# nRF7140_graphics register map
Vendor: Nordic Semiconductor; Series: nRF71; File version: 1
CPU: CM33 r0p4, little endian, MPU, FPU, 3 interrupt priority bits, 480 interrupts
Registers are 32-bit, read-write, reset 0x0 unless marked. A register's access mark holds for its fields unless they carry their own. Offsets are from the block's base; [hi:lo] are bit positions; lines under a group give offsets from that group; {n}, {i} and the like mark numbered series; 'fields as' and 'values as' point back to an identical list.

## GLOBAL_FICR_NS — Factory Information Configuration Registers
Base 0x0FFFE000
0x00 SOCINFO group — Unspecified
  0x00 PARTNO ro reset 0xFFFFFFFF — Part number.
    [31:0] PART
  0x04 HWREVISION ro reset 0xFFFFFFFF — Hardware revision.
    [31:0] HWREVISION — Hardvare revision.
  0x08 PRODUCTIONREVISION ro reset 0xFFFFFFFF — Production reversion.
0x0C BLE group — Unspecified
  0x00 ADDRTYPE ro reset 0xFFFFFFFF — Device address type.
    [0] TYPE
      0=Public address; 1=Random address
  {0x4+4j} ADDR[{j}] (j=0..1) ro reset 0xFFFFFFFF — Description collection: 48 bit device address.
    [31:0] ADDR — Device address [n].
  {0xC+4j} ER[{j}] (j=0..3) ro reset 0xFFFFFFFF — Description collection: Encryption Root.
    [31:0] ER — Encryption root word [n].
  {0x1C+4j} IR[{j}] (j=0..3) ro reset 0xFFFFFFFF — Description collection: Identity Root.
    [31:0] IR — Identity root word [n].
0x40 NFC group — Unspecified
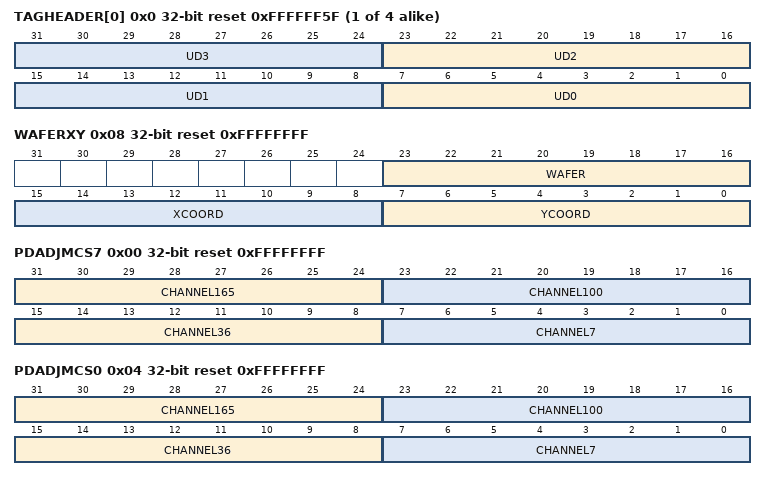
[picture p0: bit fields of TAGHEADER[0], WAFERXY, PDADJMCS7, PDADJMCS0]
  {0x0+4j} TAGHEADER[{j}] (j=0..3) ro reset 0xFFFFFF5F — Description collection: Default header for NFC Tag.
    [8n+7:8n] UD{n} (n=0..3) — Unique identifier byte {n}
0x50 INFO group — Device info
  0x00 CONFIGID ro reset 0xFFFFFFFF — Configuration identifier
    [15:0] HWID — Identification number for the HW
  0x04 PART ro reset 0xFFFFFFFF — Part code
    [31:0] PART
      0xFFFFFFFF=Unspecified
  0x08 VARIANT ro reset 0xFFFFFFFF — Part Variant, Hardware version and Production configuration
    [31:0] VARIANT — Part Variant, Hardware version and Production configuration, encoded as ASCII
      0xFFFFFFFF=Unspecified
  0x0C PACKAGE ro reset 0xFFFFFFFF — Package option
    [31:0] PACKAGE
      0xFFFFFFFF=Unspecified
  0x10 RAM ro reset 0xFFFFFFFF — RAM variant
    [31:0] RAM
      0xFFFFFFFF=Unspecified
  0x14 MRAM ro reset 0xFFFFFFFF — MRAM variant
    [31:0] MRAM
      0xFFFFFFFF=Unspecified
  0x18 CODEPAGESIZE ro reset 0x1000 — Code memory page size in bytes
    [31:0] CODEPAGESIZE
      0xFFFFFFFF=Unspecified
  0x1C CODESIZE ro reset 0x100 — Code memory size
    [31:0] CODESIZE — Code memory size in number of pages
      0xFFFFFFFF=Unspecified
  0x20 DEVICETYPE ro
    [31:0] DEVICETYPE
      0=Die (Device is an physical DIE); 0xFFFFFFFF=FPGA (Device is an FPGA)
0x80 WIFI group — Unspecified
  0x00 DISABLE5GHZ ro reset 0xFFFFFFFF
    [31:0] VALUE — Disable 5GHz support. Firmware reads at start of day. Set to 0x50FA50FA to disable 5GHz operation.
  {0x4+4j} MACADDR0[{j}] (j=0..2) ro reset 0xFFFFFFFF — Description collection: Least significant 4 bytes of default MAC address for VIF[n].
    [31:0] MACADDRLO — MAC address for VIF[n] bytes 3:0.
  {0x10+4j} MACADDR1[{j}] (j=0..2) ro reset 0xFFFFFFFF — Description collection: Most significant 2 bytes of default MAC address for VIF[n].
    [15:0] MACADDRHI — MAC address for VIF[n] bytes 5:4.
0xC0 PRODTEST group — Unspecified
  0x00 CP group — Unspecified
    {0x0+4k} LOTNR[{k}] (k=0..1) ro reset 0xFFFFFFFF — Description collection: Lot number.
      [31:0] LOTNR — Lot number
    0x08 WAFERXY ro reset 0xFFFFFFFF — Wafer number and die X,Y coordinate.
      [23:16] WAFER — Wafer number
      [15:8] XCOORD — Die x coordinate
      [7:0] YCOORD — Die y coordinate
    0x0C PROGVERSION1 ro reset 0xFFFFFFFF — CP1 test program version.
      [31:0] PROGVERSION1 — CP1 test program version
    0x10 PROGVERSION2 ro reset 0xFFFFFFFF — CP2 test program version.
      [31:0] PROGVERSION2 — CP2 test program version
  0x14 FT group — Unspecified
    0x00 PROGVERSION1 ro reset 0xFFFFFFFF — FT1 test program version.
      [31:0] PROGVERSION1 — FT1 test program version
    0x04 PROGVERSION2 ro reset 0xFFFFFFFF — FT2 test program version.
      [31:0] PROGVERSION2 — FT2 test program version
0x100 TRIM group — Unspecified
  0x00 SYSCTRL group — Unspecified
    0x00 FLL16M group — Unspecified
      0x00 TRIM group — Unspecified
        0x00 RCOARSE ro reset 0xFFFFFFFF — Trim value for SYSCTRL.FLL16M.RCOARSE
          [31:0] VALUE — Trim value
        0x04 RFINE ro reset 0xFFFFFFFF — Trim value for SYSCTRL.FLL16M.RFINE
          [31:0] VALUE — Trim value
        0x08 TCOEF ro reset 0xFFFFFFFF — Trim value for SYSCTRL.FLL16M.TCOEF
          [31:0] VALUE — Trim value
        0x0C VSUP ro reset 0xFFFFFFFF — Trim value for SYSCTRL.FLL16M.VSUP
          [31:0] VALUE — Trim value
        0x10 CKSW16MTRIM ro reset 0xFFFFFFFF — Trim value for SYSCTRL.FLL16M.CKSW16MTRIM
          [31:0] VALUE — Trim value
    0x14 LFRC group — Unspecified
      0x00 CAL group — Unspecified
        0x00 LFRCOSCTRIM ro reset 0xFFFFFFFF — Trim value for SYSCTRL.LFRC.LFRCOSCTRIM
          [31:0] VALUE — Trim value
    0x18 LFXO group — Unspecified
      0x00 TRIM group — Unspecified
        0x00 PDLOWERTHR ro reset 0xFFFFFFFF — Trim value for SYSCTRL.LFXO.PDLOWERTHR
          [31:0] VALUE — Trim value
        0x04 PDUPPERTHR ro reset 0xFFFFFFFF — Trim value for SYSCTRL.LFXO.PDUPPERTHR
          [31:0] VALUE — Trim value
        0x08 BIAS ro reset 0xFFFFFFFF — Trim value for SYSCTRL.LFXO.BIAS
          [31:0] VALUE — Trim value
        0x0C PIXO ro reset 0xFFFFFFFF — Trim value for SYSCTRL.LFXO.PIXO
          [31:0] VALUE — Trim value
        0x10 TRIMBUS ro reset 0xFFFFFFFF — Trim value for SYSCTRL.LFXO.TRIMBUS
          [31:0] VALUE — Trim value
    0x2C HFXO64M group — Unspecified
      0x00 TRIM group — Unspecified
        0x00 DOUBLERCOMP ro reset 0xFFFFFFFF — Trim value for SYSCTRL.HFXO64M.TRIM.DOUBLERCOMP
          [31:0] VALUE — Trim value
        0x04 CHIRPTUNE ro reset 0xFFFFFFFF — Trim value for SYSCTRL.HFXO64M.TRIM.CHIRPTUNE
          [31:0] VALUE — Trim value
        0x08 RTUNE ro reset 0xFFFFFFFF — Trim value for SYSCTRL.HFXO64M.TRIM.RTUNE
          [31:0] VALUE — Trim value
    0x38 LFLPRC group — Unspecified
      0x00 VSUP ro reset 0xFFFFFFFF — Trim value for SYSCTRL.LFLPRC.VSUP
        [31:0] VALUE — Trim value
      0x04 RCOARSE ro reset 0xFFFFFFFF — Trim value for SYSCTRL.LFLPRC.RCOARSE
        [31:0] VALUE — Trim value
      0x08 RFINE ro reset 0xFFFFFFFF — Trim value for SYSCTRL.LFLPRC.RFINE
        [31:0] VALUE — Trim value
      0x0C PWMFINE ro reset 0xFFFFFFFF — Trim value for SYSCTRL.LFLPRC.PWMFINE
        [31:0] VALUE — Trim value
    0x48 VDETPOF5V0 group (alternate view of LFLPRC) — Unspecified
      0x00 TRIM group — Unspecified
        0x00 PWRGOOD ro reset 0xFFFFFFFF — Trim value for SYSCTRL.VDETPOF5V0.PWRGOOD
          [31:0] VALUE — Trim value
    0x4C VDETPOFVBAT group (alternate view of LFLPRC) — Unspecified
      0x00 TRIM group — Unspecified
        0x00 POFWARN ro reset 0xFFFFFFFF — Trim value for SYSCTRL.VDETPOFVBAT.POFWARN
          [31:0] VALUE — Trim value
    0x54 AUDIOPLL group — Unspecified
      0x00 TRIM group — Unspecified
        0x00 CTUNE ro reset 0xFFFFFFFF — Trim value for SYSCTRL.AUDIOPLL.CTUNE
          [31:0] VALUE — Trim value
    0x58 USBHSPLL group — Unspecified
      0x00 TRIM group — Unspecified
        0x00 CTUNE ro reset 0xFFFFFFFF — Trim value for SYSCTRL.USBHSPLL.CTUNE
          [31:0] VALUE — Trim value
    0x5C MBIAS group — Unspecified
      0x00 CONFIG group — Unspecified
        0x00 CFG ro reset 0xFFFFFFFF — Trim value for SYSCTRL.MBIAS.CFG
          [31:0] VALUE — Trim value
      0x04 TRIM group — Unspecified
        0x00 MBIASIBPP ro reset 0xFFFFFFFF — Trim value for SYSCTRL.MBIAS.MBIASIBPP
          [31:0] VALUE — Trim value
        0x04 MBIASIBPSR ro reset 0xFFFFFFFF — Trim value for SYSCTRL.MBIAS.MBIASIBPSR
          [31:0] VALUE — Trim value
    0x68 OSCRFR group — Unspecified
      0x00 TRIM group — Unspecified
        0x00 OSC ro reset 0xFFFFFFFF — Trim value for SYSCTRL.OSCRFR.OSC
          [31:0] VALUE — Trim value
        0x04 IBPSR ro reset 0xFFFFFFFF — Trim value for SYSCTRL.OSCRFR.IBPSR
          [31:0] VALUE — Trim value
    0x70 VREG1V0 group — Unspecified
      0x00 TRIM group — Unspecified
        0x00 IREF ro reset 0xFFFFFFFF — Trim value for SYSCTRL.VREG1V0.IREF
          [31:0] VALUE — Trim value
        0x04 HIGHPOWER ro reset 0xFFFFFFFF — Trim value for SYSCTRL.VREG1V0.HIGHPOWER
          [31:0] VALUE — Trim value
        0x08 LOWPOWER ro reset 0xFFFFFFFF — Trim value for SYSCTRL.VREG1V0.LOWPOWER
          [31:0] VALUE — Trim value
        0x0C ULPR ro reset 0xFFFFFFFF — Trim value for SYSCTRL.VREG1V0.ULPR
          [31:0] VALUE — Trim value
      0x10 VOUTHPNOMINAL ro reset 0xFFFFFFFF — Config value for SYSCTRL.VREG1V0.VOUTHPNOMINAL
        [31:0] VALUE — Trim value
    0x84 VREGAO0V8 group — Unspecified
      0x00 TRIM group — Unspecified
        0x00 IREF ro reset 0xFFFFFFFF — Trim value for SYSCTRL.VREGAO0V8.IREF
          [31:0] VALUE — Trim value
        0x04 HIGHPOWER ro reset 0xFFFFFFFF — Trim value for SYSCTRL.VREGAO0V8.HIGHPOWER
          [31:0] VALUE — Trim value
        0x08 LOWPOWER ro reset 0xFFFFFFFF — Trim value for SYSCTRL.VREGAO0V8.LOWPOWER
          [31:0] VALUE — Trim value
        0x0C ULTRALOWPOWER ro reset 0xFFFFFFFF — Trim value for SYSCTRL.VREGAO0V8.ULTRALOWPOWER
          [31:0] VALUE — Trim value
        0x10 BPDET ro reset 0xFFFFFFFF — Trim value for SYSCTRL.VREGAO0V8.BPDET
          [31:0] VALUE — Trim value
    0x98 VREGAO1V8 group — Unspecified
      0x00 TRIM group — Unspecified
        0x00 IREF ro reset 0xFFFFFFFF — Trim value for SYSCTRL.VREGAO1V8.IREF
          [31:0] VALUE — Trim value
        0x04 VREF ro reset 0xFFFFFFFF — Trim value for SYSCTRL.VREGAO1V8.VREF
          [31:0] VALUE — Trim value
        0x08 LOWPOWER ro reset 0xFFFFFFFF — Trim value for SYSCTRL.VREGAO1V8.LOWPOWER
          [31:0] VALUE — Trim value
        0x0C LOWPOWERDIFF ro reset 0xFFFFFFFF — Trim value for SYSCTRL.VREGAO1V8.LOWPOWERDIFF
          [31:0] VALUE — Trim value
    0xA8 VREGMAIN group — Unspecified
      0x00 TRIM group — Unspecified
        0x00 BIASIBPP ro reset 0xFFFFFFFF — Trim value for SYSCTRL.VREGMAIN.BIASIBPP
          [31:0] VALUE — Trim value
        0x04 BIASIBPSR ro reset 0xFFFFFFFF — Trim value for SYSCTRL.VREGMAIN.BIASIBPSR
          [31:0] VALUE — Trim value
        0x08 VDDAO1V8HYSTOUTPUT ro reset 0xFFFFFFFF — Trim value for SYSCTRL.VREGMAIN.VDDAO1V8HYSTOUTPUT
          [31:0] VALUE — Trim value
        0x0C VDDAO1V8PWMOUTPUT ro reset 0xFFFFFFFF — Trim value for SYSCTRL.VREGMAIN.VDDAO1V8PWMOUTPUT
          [31:0] VALUE — Trim value
        0x10 VDD1V0HYSTOUTPUT ro reset 0xFFFFFFFF — Trim value for SYSCTRL.VREGMAIN.VDD1V0HYSTOUTPUT
          [31:0] VALUE — Trim value
        0x14 VDDVS0V8HYSTOUTPUT ro reset 0xFFFFFFFF — Trim value for SYSCTRL.VREGMAIN.VDDVS0V8HYSTOUTPUT
          [31:0] VALUE — Trim value
        0x18 VDDVS0V8PWMOUTPUT ro reset 0xFFFFFFFF — Trim value for SYSCTRL.VREGMAIN.VDDVS0V8PWMOUTPUT
          [31:0] VALUE — Trim value
        0x1C VDD1V0PWMOUTPUT ro reset 0xFFFFFFFF — Trim value for SYSCTRL.VREGMAIN.VDD1V0PWMOUTPUT
          [31:0] VALUE — Trim value
        0x20 ZCROSS ro reset 0xFFFFFFFF — Trim value for SYSCTRL.VREGMAIN.ZCROSS
          [31:0] VALUE — Trim value
        0x24 HSILIM ro reset 0xFFFFFFFF — Trim value for SYSCTRL.VREGMAIN.HSILIM
          [31:0] VALUE — Trim value
        0x28 ICMP ro reset 0xFFFFFFFF — Trim value for SYSCTRL.VREGMAIN.ICMP
          [31:0] VALUE — Trim value
        0x2C VGND ro reset 0xFFFFFFFF — Trim value for SYSCTRL.VREGMAIN.VGND
          [31:0] VALUE — Trim value
    0xD8 VREGMRAM130 group — Unspecified
      0x00 TRIM group — Unspecified
        0x00 VBG ro reset 0xFFFFFFFF — Trim value for SYSCTRL.VREGMRAM130.VBG
          [31:0] VALUE — Trim value
        0x04 BIAS ro reset 0xFFFFFFFF — Trim value for SYSCTRL.VREGMRAM130.BIAS
          [31:0] VALUE — Trim value
        0x08 VPR ro reset 0xFFFFFFFF — Trim value for SYSCTRL.VREGMRAM130.VPR
          [31:0] VALUE — Trim value
        0x0C VREF ro reset 0xFFFFFFFF — Trim value for SYSCTRL.VREGMRAM130.VREF
          [31:0] VALUE — Trim value
    0xE8 VREGMRAM131 group — Unspecified
      0x00 TRIM group — Unspecified
        0x00 VBG ro reset 0xFFFFFFFF — Trim value for SYSCTRL.VREGMRAM131.VBG
          [31:0] VALUE — Trim value
        0x04 BIAS ro reset 0xFFFFFFFF — Trim value for SYSCTRL.VREGMRAM131.BIAS
          [31:0] VALUE — Trim value
        0x08 VPR ro reset 0xFFFFFFFF — Trim value for SYSCTRL.VREGMRAM131.VPR
          [31:0] VALUE — Trim value
        0x0C VREF ro reset 0xFFFFFFFF — Trim value for SYSCTRL.VREGMRAM131.VREF
          [31:0] VALUE — Trim value
    0xF8 VREGVS0V8 group — Unspecified
      0x00 TRIM group — Unspecified
        0x00 IREF ro reset 0xFFFFFFFF — Trim value for SYSCTRL.VREGVS0V8.IREF
          [31:0] VALUE — Trim value
        0x04 HIGHPOWER ro reset 0xFFFFFFFF — Trim value for SYSCTRL.VREGVS0V8.HIGHPOWER
          [31:0] VALUE — Trim value
        0x08 LOWPOWER ro reset 0xFFFFFFFF — Trim value for SYSCTRL.VREGVS0V8.LOWPOWER
          [31:0] VALUE — Trim value
        0x0C ULPR ro reset 0xFFFFFFFF — Trim value for SYSCTRL.VREGVS0V8.ULPR
          [31:0] VALUE — Trim value
    0x108 VREGUSB group — Unspecified
      0x00 TRIM group — Unspecified
        0x00 TRIMVDD ro reset 0xFFFFFFFF — Trim value for SYSCTRL.VREGUSB.TRIMVDD
          [31:0] VALUE — Trim value
        0x04 TRIMIBP ro reset 0xFFFFFFFF — Trim value for SYSCTRL.VREGUSB.TRIMIBP
          [31:0] VALUE — Trim value
        0x08 TRIM0V8 ro reset 0xFFFFFFFF — Trim value for SYSCTRL.VREGUSB.TRIM0V8
          [31:0] VALUE — Trim value
        0x0C TRIM3V3 ro reset 0xFFFFFFFF — Trim value for SYSCTRL.VREGUSB.TRIM3V3
          [31:0] VALUE — Trim value
    0x118 VDETAO0V8 group — Unspecified
      0x00 TRIM group — Unspecified
        0x00 BROWNOUT ro reset 0xFFFFFFFF — Trim value for SYSCTRL.VDETAO0V8.BROWNOUT
          [31:0] VALUE — Trim value
        0x04 PWRGOOD ro reset 0xFFFFFFFF — Trim value for SYSCTRL.VDETAO0V8.PWRGOOD
          [31:0] VALUE — Trim value
      0x08 CONFIG group — Unspecified
        0x00 BROWNOUTHP ro reset 0xFFFFFFFF — Config value for SYSCTRL.VDETAO0V8.CONFIG.BROWNOUTHP
          [31:0] VALUE — Trim value
    0x124 VDETAO1V8 group — Unspecified
      0x00 TRIM group — Unspecified
        0x00 BROWNOUTLVLHIGH ro reset 0xFFFFFFFF — Trim value for SYSCTRL.VDETAO1V8.BROWNOUTLVLHIGH
          [31:0] VALUE — Trim value
        0x04 BROWNOUTLVLLOW ro reset 0xFFFFFFFF — Trim value for SYSCTRL.VDETAO1V8.BROWNOUTLVLLOW
          [31:0] VALUE — Trim value
    0x12C VDETVS0V8 group — Unspecified
      0x00 TRIM group — Unspecified
        0x00 BROWNOUT ro reset 0xFFFFFFFF — Trim value for SYSCTRL.VDETVS0V8.BROWNOUT
          [31:0] VALUE — Trim value
        0x04 PWRGOOD ro reset 0xFFFFFFFF — Trim value for SYSCTRL.VDETVS0V8.PWRGOOD
          [31:0] VALUE — Trim value
    0x134 VDETAO5V0 group — Unspecified
      0x00 TRIM group — Unspecified
        0x00 PWRGOOD ro reset 0xFFFFFFFF — Trim value for SYSCTRL.VDETAO5V0.PWRGOOD
          [31:0] VALUE — Trim value
    0x138 VDET1V0 group — Unspecified
      0x00 TRIM group — Unspecified
        0x00 PWRGOOD ro reset 0xFFFFFFFF — Trim value for SYSCTRL.VDET1V0.PWRGOOD
          [31:0] VALUE — Trim value
    0x13C HSFLL120 group — Unspecified
      0x00 TRIM group — Unspecified
        0x00 VSUP ro reset 0xFFFFFFFF — Trim value for SYSCTRL.HSFLL120.VSUP
          [31:0] VALUE — Trim value
        {0x4+4m} COARSE[{m}] (m=0..5) ro reset 0xFFFFFFFF — Description collection: Trim value for SYSCTRL.HSFLL120.COARSE
          [31:0] VALUE — Trim value
        {0x1C+4m} FINE[{m}] (m=0..5) ro reset 0xFFFFFFFF — Description collection: Trim value for SYSCTRL.HSFLL120.FINE
          [31:0] VALUE — Trim value
    0x170 HSFLL121 group — Unspecified
      0x00 TRIM group — Unspecified
        0x00 VSUP ro reset 0xFFFFFFFF — Trim value for SYSCTRL.HSFLL121.VSUP
          [31:0] VALUE — Trim value
        {0x4+4m} COARSE[{m}] (m=0..5) ro reset 0xFFFFFFFF — Description collection: Trim value for SYSCTRL.HSFLL121.COARSE
          [31:0] VALUE — Trim value
        {0x1C+4m} FINE[{m}] (m=0..5) ro reset 0xFFFFFFFF — Description collection: Trim value for SYSCTRL.HSFLL121.FINE
          [31:0] VALUE — Trim value
    0x1A4 MEMCONF120 group — Unspecified
      {0x0+4l} REPAIR[{l}] (l=0..35) group — Unspecified
        0x00 BITLINE ro reset 0xFFFFFFFF — Description cluster: Trim value for SYSCTRL.MEMCONF120.REPAIR[n].BITLINE
          [31:0] VALUE — Trim value
      {0xB0+4l} BLOCKTYPE[{l}] (l=0..7) group — Unspecified
        0x00 TRIM ro reset 0xFFFFFFFF — Description cluster: Trim value for SYSCTRL.MEMCONF120.TRIM
          [31:0] VALUE — Trim value
    0x274 MEMCONF130 group — Unspecified
      {0x0+4l} BLOCKTYPE[{l}] (l=0..1) group — Unspecified
        0x00 TRIM ro reset 0xFFFFFFFF — Description cluster: Trim value for SYSCTRL.MEMCONF130.TRIM
          [31:0] VALUE — Trim value
  0x27C GLOBAL group — Unspecified
    0x00 SAADC group — Unspecified
      0x00 CALVREF ro reset 0xFFFFFFFF — Trim value for GLOBAL.SAADC.CALVREF
        [31:0] VALUE — Trim value
      {0x4+4l} CALGAIN[{l}] (l=0..2) ro reset 0xFFFFFFFF — Description collection: Trim value for GLOBAL.SAADC.CALGAIN
        [31:0] VALUE — Trim value
      0x10 CALOFFSET ro reset 0xFFFFFFFF — Trim value for GLOBAL.SAADC.CALOFFSET
        [31:0] VALUE — Trim value
      {0x14+4l} LINCALCOEFF[{l}] (l=0..5) ro reset 0xFFFFFFFF — Description collection: Trim value for GLOBAL.SAADC.LINCALCOEFF
        [31:0] VALUE — Trim value
      0x2C CALIREF ro reset 0xFFFFFFFF — Trim value for GLOBAL.SAADC.CALIREF
        [31:0] VALUE — Trim value
    0x30 TEMP group — Unspecified
      {0x0+4l} A[{l}] (l=0..5) ro reset 0xFFFFFFFF — Description collection: Trim value for GLOBAL.TEMP.A
        [31:0] VALUE — Trim value
      {0x18+4l} B[{l}] (l=0..5) ro reset 0xFFFFFFFF — Description collection: Trim value for GLOBAL.TEMP.B
        [31:0] VALUE — Trim value
      {0x30+4l} T[{l}] (l=0..4) ro reset 0xFFFFFFFF — Description collection: Trim value for GLOBAL.TEMP.T
        [31:0] VALUE — Trim value
    0x74 NFCT group — Unspecified
      0x00 BIASCFG ro reset 0xFFFFFFFF — Trim value for NFCT.BIASCFG
        [31:0] VALUE — Trim value
    0x78 CANPLL group — Unspecified
      0x00 TRIM group — Unspecified
        0x00 CTUNE ro reset 0xFFFFFFFF — Trim value for GLOBAL.CANPLL.CTUNE
          [31:0] VALUE — Trim value
    0x7C GPIO group — Unspecified
      0x00 PORTCNF group — Unspecified
        0x00 DRIVECTRL group — Unspecified
          {0x0+4p} P[{p}] (p=0..1) ro reset 0xFFFFFFFF — Description collection: Trim value for GPIO.Pn.PORTCNF.DRIVECTRL
            [31:0] VALUE — Trim value
  0x300 APPLICATION group — Unspecified
    0x00 HSFLL group — Unspecified
      0x00 TRIM group — Unspecified
        0x00 VSUP ro reset 0xFFFFFFFF — Trim value for APPLICATION.HSFLL.VSUP
          [31:0] VALUE — Trim value
        {0x4+4m} COARSE[{m}] (m=0..5) ro reset 0xFFFFFFFF — Description collection: Trim value for APPLICATION.HSFLL.COARSE
          [31:0] VALUE — Trim value
        {0x1C+4m} FINE[{m}] (m=0..5) ro reset 0xFFFFFFFF — Description collection: Trim value for APPLICATION.HSFLL.FINE
          [31:0] VALUE — Trim value
    0x34 MEMCONF group — Unspecified
      {0x0+4l} BLOCKTYPE[{l}] (l=0..2) group — Unspecified
        0x00 TRIM ro reset 0xFFFFFFFF — Description cluster: Trim value for APPLICATION.MEMCONF.TRIM
          [31:0] VALUE — Trim value
  0x340 RADIOCORE group — Unspecified
    0x00 HSFLL group — Unspecified
      0x00 TRIM group — Unspecified
        0x00 VSUP ro reset 0xFFFFFFFF — Trim value for RADIOCORE.HSFLL.VSUP
          [31:0] VALUE — Trim value
        {0x4+4m} COARSE[{m}] (m=0..5) ro reset 0xFFFFFFFF — Description collection: Trim value for RADIOCORE.HSFLL.COARSE
          [31:0] VALUE — Trim value
        {0x1C+4m} FINE[{m}] (m=0..5) ro reset 0xFFFFFFFF — Description collection: Trim value for RADIOCORE.HSFLL.FINE
          [31:0] VALUE — Trim value
    0x34 MEMCONF group — Unspecified
      {0x0+4l} BLOCKTYPE[{l}] (l=0..2) group — Unspecified
        0x00 TRIM ro reset 0xFFFFFFFF — Description cluster: Trim value for RADIOCORE.MEMCONF.TRIM
          [31:0] VALUE — Trim value
    0x40 RADIO group — Unspecified
      0x00 SPHYNXANA group — Unspecified
        0x00 FSCTRL1 ro reset 0xFFFFFFFF — Trim value for RADIOCORE.RADIO.FSCTRL1
          [31:0] VALUE — Trim value
        0x04 FSCTRL2 ro reset 0xFFFFFFFF — Trim value for RADIOCORE.RADIO.FSCTRL2
          [31:0] VALUE — Trim value
        0x08 RXCTRL ro reset 0xFFFFFFFF — Trim value for RADIOCORE.RADIO.RXCTRL
          [31:0] VALUE — Trim value
        0x0C TXCTRL ro reset 0xFFFFFFFF — Trim value for RADIOCORE.RADIO.TXCTRL
          [31:0] VALUE — Trim value
        0x10 OVRRXTRIMCODE ro reset 0xFFFFFFFF — Trim value for RADIOCORE.RADIO.OVRRXTRIMCODE
          [31:0] VALUE — Trim value
      0x14 RSSIOFFSET ro reset 0xFFFFFFFF — Trim value for RSSI offset compensation
        [31:0] VALUE — Trim value
      0x18 EDCAL ro reset 0xFFFFFFFF — Trim value for EDCAL
        [31:0] VALUE — Trim value
  0x3E0 BOOT group — Unspecified
    0x00 HSFLL120 group — Unspecified
      0x00 VSUP ro reset 0xFFFFFFFF — Trim value for SYSCTRL.HSFLL120.VSUP
        [31:0] VALUE — Trim value
      0x04 COARSE ro reset 0xFFFFFFFF — Trim value for SYSCTRL.HSFLL120.COARSE
        [31:0] VALUE — Trim value
      0x08 FINE ro reset 0xFFFFFFFF — Trim value for SYSCTRL.HSFLL120.FINE
        [31:0] VALUE — Trim value
    0x0C OTPC group — Unspecified
      0x00 WAITSTATES ro reset 0xFFFFFFFF — OTPC waitstates trim when running with TRIM.BOOT.HSFLL120 trims
        [6:0] WAITSTATES
      0x04 FREQUENCY ro reset 0xFFFFFFFF — OTPC frequency tim when running with TRIM.BOOT.HSFLL120 trims
        [31:0] FREQUENCY — Trim value
  0x3F8 COMMON group — Unspecified
    0x00 ZERO ro reset 0xFFFFFFFF — Value to be written to MIRROR register in MMIs (MIRROR=0)
      [31:0] ZERO — Mirror register value
    0x04 ONE ro reset 0xFFFFFFFF — Value to be written to MIRROR register in MMIs (MIRROR=1)
      [31:0] ONE — Mirror register value
  0x400 SECURE group — Unspecified
    0x00 HSFLL group — Unspecified
      0x00 TRIM group — Unspecified
        0x00 VSUP ro reset 0xFFFFFFFF — Trim value for SECURE.HSFLL.VSUP
          [31:0] VALUE — Trim value
        {0x4+4m} COARSE[{m}] (m=0..5) ro reset 0xFFFFFFFF — Description collection: Trim value for SECURE.HSFLL.COARSE
          [31:0] VALUE — Trim value
        {0x1C+4m} FINE[{m}] (m=0..5) ro reset 0xFFFFFFFF — Description collection: Trim value for SECURE.HSFLL.FINE
          [31:0] VALUE — Trim value
    0x34 HSFLL200 group — Unspecified
      0x00 TRIM group — Unspecified
        0x00 VSUP ro reset 0xFFFFFFFF — Trim value for SECURE.HSFLL200.VSUP
          [31:0] VALUE — Trim value
        {0x4+4m} COARSE[{m}] (m=0..3) ro reset 0xFFFFFFFF — Description collection: Trim value for SECURE.HSFLL200.COARSE
          [31:0] VALUE — Trim value
        {0x14+4m} FINE[{m}] (m=0..3) ro reset 0xFFFFFFFF — Description collection: Trim value for SECURE.HSFLL200.FINE
          [31:0] VALUE — Trim value
    0x58 MEMCONF group — Unspecified
      {0x0+4l} BLOCKTYPE[{l}] (l=0..6) group — Unspecified
        0x00 TRIM ro reset 0xFFFFFFFF — Description cluster: Trim value for SECURE.MEMCONF.BLOCKTYPE[n].TRIM
          [31:0] VALUE — Trim value
    0x74 MEMCONF200 group — Unspecified
      0x00 BLOCKTYPE group — Unspecified
        0x00 TRIM ro reset 0xFFFFFFFF — Trim value for SECURE.MEMCONF200.TRIM
          [31:0] VALUE — Trim value
  0x500 WIFICORE group — Unspecified
    0x00 HSFLL group — Unspecified
      0x00 VSUP ro reset 0xFFFFFFFF — Trim value for WIFICORE.HSFLL.VSUP
        [31:0] VALUE — Trim value
      0x04 COARSE ro reset 0xFFFFFFFF — Trim value for WIFICORE.HSFLL.COARSE
        [31:0] VALUE — Trim value
      0x08 FINE ro reset 0xFFFFFFFF — Trim value for WIFICORE.HSFLL.FINE
        [31:0] VALUE — Trim value
    0x0C MEMCONF group — Unspecified
      {0x0+4l} REPAIR[{l}] (l=0..22) group — Unspecified
        0x00 BITLINE ro reset 0xFFFFFFFF — Description cluster: Trim value for WIFICORE.MEMCONF.REPAIR[n].BITLINE
          [31:0] VALUE — Trim value
      {0x5C+4l} BLOCKTYPE[{l}] (l=0..3) group — Unspecified
        0x00 TRIM ro reset 0xFFFFFFFF — Description cluster: Trim value for WIFICORE.MEMCONF.BLOCKTYPE[n].TRIM
          [31:0] VALUE — Trim value
    0x78 RADIO group — Unspecified
      0x00 PDADJMCS7 ro reset 0xFFFFFFFF — Power detector adjustment for MCS7 for channel 7, 36, 100, 165
        [31:24] CHANNEL165 — Trim value for channel 165 (units of 0.25dB)
        [23:16] CHANNEL100 — Trim value for channel 100 (units of 0.25dB)
        [15:8] CHANNEL36 — Trim value for channel 36 (units of 0.25dB)
        [7:0] CHANNEL7 — Trim value for channel 7 (units of 0.25dB)
      0x04 PDADJMCS0 ro reset 0xFFFFFFFF — Power detector adjustment for MCS0 for channel 7, 36, 100, 165
        fields as TRIM.WIFICORE.RADIO.PDADJMCS7
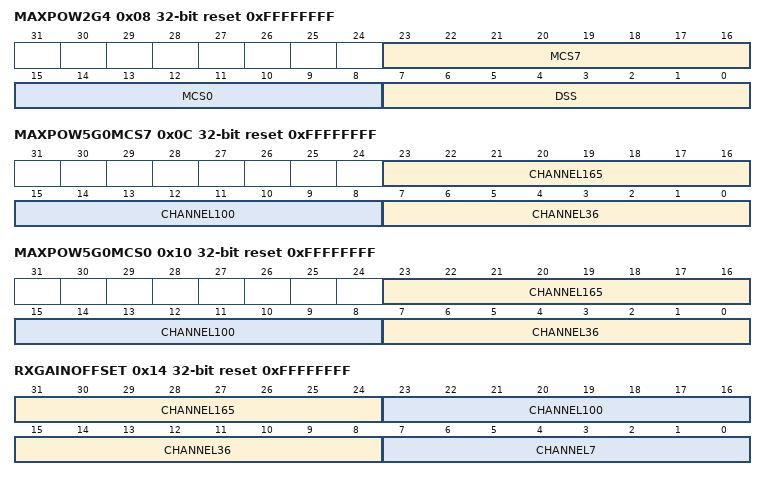
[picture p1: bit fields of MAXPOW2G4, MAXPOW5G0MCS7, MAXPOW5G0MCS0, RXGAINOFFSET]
      0x08 MAXPOW2G4 ro reset 0xFFFFFFFF — Maximum output power 2GHz band, channel 7
        [23:16] MCS7 — Trim value for channel 7 MCS7 (units of 0.25dBm)
        [15:8] MCS0 — Trim value for channel 7 MCS0 (units of 0.25dBm)
        [7:0] DSS — Trim value for channel 7 DSS (units of 0.25dBm)
      0x0C MAXPOW5G0MCS7 ro reset 0xFFFFFFFF — Maximum output power 5GHz band, MCS7
        [23:16] CHANNEL165 — Trim value for channel 165 MCS7 (units of 0.25dBm)
        [15:8] CHANNEL100 — Trim value for channel 100 MCS7 (units of 0.25dBm)
        [7:0] CHANNEL36 — Trim value for channel 36 MCS7 (units of 0.25dBm)
      0x10 MAXPOW5G0MCS0 ro reset 0xFFFFFFFF — Maximum output power 5GHz band, MCS0
        [23:16] CHANNEL165 — Trim value for channel 165 MCS0 (units of 0.25dBm)
        [15:8] CHANNEL100 — Trim value for channel 100 MCS0 (units of 0.25dBm)
        [7:0] CHANNEL36 — Trim value for channel 36 MCS0 (units of 0.25dBm)
      0x14 RXGAINOFFSET ro reset 0xFFFFFFFF — RX gain offset for channel 7, 36, 100, 165
        fields as TRIM.WIFICORE.RADIO.PDADJMCS7
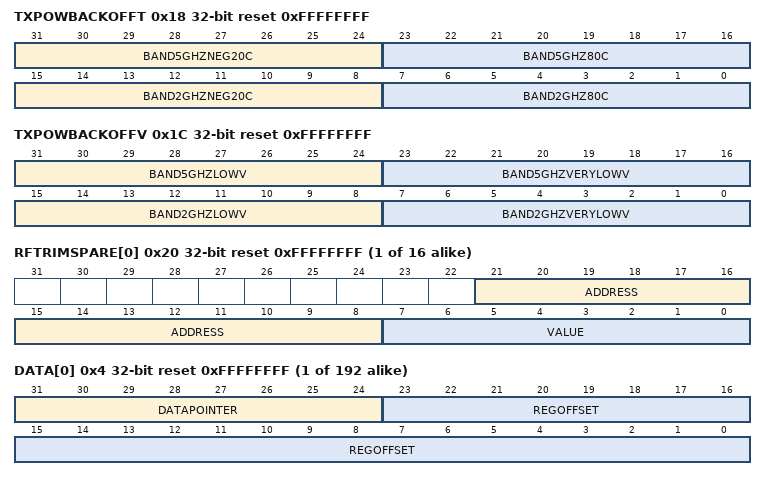
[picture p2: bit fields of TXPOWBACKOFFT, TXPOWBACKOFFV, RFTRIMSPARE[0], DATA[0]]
      0x18 TXPOWBACKOFFT ro reset 0xFFFFFFFF — TX power backoff versus temperature
        [31:24] BAND5GHZNEG20C — Trim value 5GHz band at -20C (units of 0.25dB)
        [23:16] BAND5GHZ80C — Trim value 5GHz band at 80C (units of 0.25dB)
        [15:8] BAND2GHZNEG20C — Trim value 2.4GHz band at -20C (units of 0.25dB)
        [7:0] BAND2GHZ80C — Trim value 2.4GHz band at 80C (units of 0.25dB)
      0x1C TXPOWBACKOFFV ro reset 0xFFFFFFFF — TX power backoff versus voltage
        [31:24] BAND5GHZLOWV — Trim value 5GHz band at low voltage (units of 0.25dB)
        [23:16] BAND5GHZVERYLOWV — Trim value 5GHz band at very low voltage (units of 0.25dB)
        [15:8] BAND2GHZLOWV — Trim value 2.4GHz band at low voltage (units of 0.25dB)
        [7:0] BAND2GHZVERYLOWV — Trim value 2.4GHz band at very low voltage (units of 0.25dB)
      {0x20+4l} RFTRIMSPARE[{l}] (l=0..15) ro reset 0xFFFFFFFF — Description collection: Arbitrary RF register trim
        [21:8] ADDRESS — Register address to apply trim value to. Address 0x3FFF indicates unused trim value.
        [7:0] VALUE — Trim value to apply
  0x600 GRAPHICSDOMAIN group — Unspecified
    0x00 HSFLL group — Unspecified
      0x00 VSUP ro reset 0xFFFFFFFF — Trim value for GRAPHICSDOMAIN.HSFLL.VSUP
        [31:0] VALUE — Trim value
      0x04 COARSE ro reset 0xFFFFFFFF — Trim value for GRAPHICSDOMAIN.HSFLL.COARSE
        [31:0] VALUE — Trim value
      0x08 FINE ro reset 0xFFFFFFFF — Trim value for GRAPHICSDOMAIN.HSFLL.FINE
        [31:0] VALUE — Trim value
    0x0C MEMCONF group — Unspecified
      {0x0+4l} BLOCKTYPE[{l}] (l=0..4) group — Unspecified
        0x00 TRIM ro reset 0xFFFFFFFF — Description cluster: Trim value for GRAPHICSDOMAIN.MEMCONF.BLOCKTYPE[n].TRIM
          [31:0] VALUE — Trim value
    0x20 AUXPLL group — Unspecified
      0x00 TRIM group — Unspecified
        0x00 CTUNE ro reset 0xFFFFFFFF — Trim value for GRAPHICSDOMAIN.AUXPLL.CTUNE
          [31:0] VALUE — Trim value
0x8A0 BOOT group — Unspecified
  0x00 SIZE ro reset 0xFFFFFFFF — Size of DATA group
    [31:0] VALUE — Number of trim values stored in DATA.
  {0x4+4j} DATA[{j}] (j=0..191) ro reset 0xFFFFFFFF — Description collection: Compressed address and data pointer.
    [31:24] DATAPOINTER — Pointer to location in TRIM group
    [23:0] REGOFFSET — Address offset to trim register
0xBB0 SRAM group — Unspecified
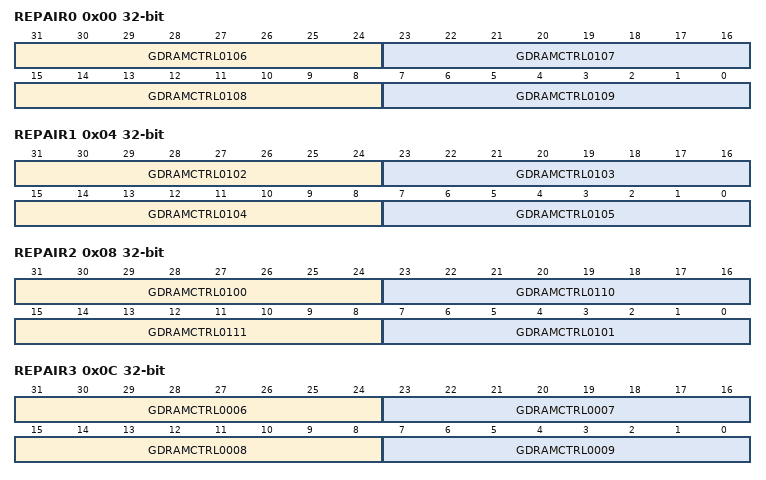
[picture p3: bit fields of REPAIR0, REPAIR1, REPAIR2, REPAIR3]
  0x00 REPAIR0 — SRAM repair register 0
    [879-8n:872-8n] GDRAMCTRL{n:04} (n=106..109) — GD RamController01 Ram {n-100}
  0x04 REPAIR1 — SRAM repair register 1
    [847-8n:840-8n] GDRAMCTRL{n:04} (n=102..105) — GD RamController01 Ram {n-100}
  0x08 REPAIR2 — SRAM repair register 2
    [31:24] GDRAMCTRL0100 — GD RamController01 Ram 0
    [23:16] GDRAMCTRL0110 — GD RamController01 Ram 10
    [15:8] GDRAMCTRL0111 — GD RamController01 Ram 11
    [7:0] GDRAMCTRL0101 — GD RamController01 Ram 1
  0x0C REPAIR3 — SRAM repair register 3
    [79-8n:72-8n] GDRAMCTRL{n:04} (n=6..9) — GD RamController00 Ram {n}
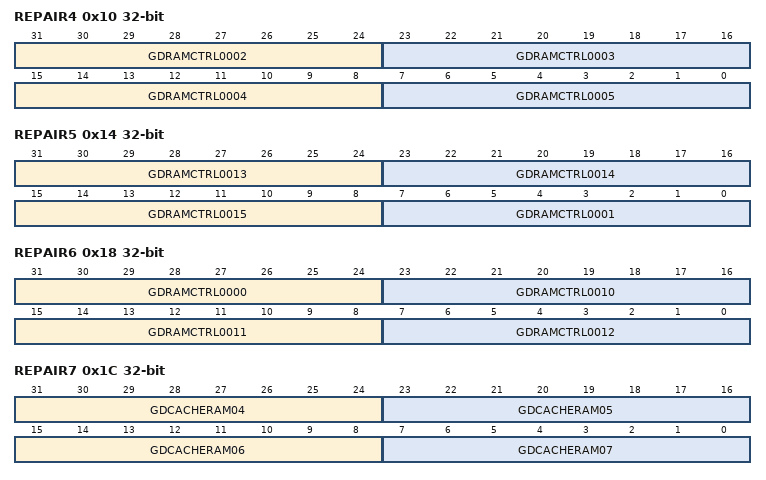
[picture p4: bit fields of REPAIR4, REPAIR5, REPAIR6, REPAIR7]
  0x10 REPAIR4 — SRAM repair register 4
    [47-8n:40-8n] GDRAMCTRL{n:04} (n=2..5) — GD RamController00 Ram {n}
  0x14 REPAIR5 — SRAM repair register 5
    [31:24] GDRAMCTRL0013 — GD RamController00 Ram 13
    [23:16] GDRAMCTRL0014 — GD RamController00 Ram 14
    [15:8] GDRAMCTRL0015 — GD RamController00 Ram 15
    [7:0] GDRAMCTRL0001 — GD RamController00 Ram 1
  0x18 REPAIR6 — SRAM repair register 6
    [31:24] GDRAMCTRL0000 — GD RamController00 Ram 0
    [23:16] GDRAMCTRL0010 — GD RamController00 Ram 10
    [15:8] GDRAMCTRL0011 — GD RamController00 Ram 11
    [7:0] GDRAMCTRL0012 — GD RamController00 Ram 12
  0x1C REPAIR7 — SRAM repair register 7
    [63-8n:56-8n] GDCACHERAM{n:02} (n=4..7) — GD Cache Data Ram {n}
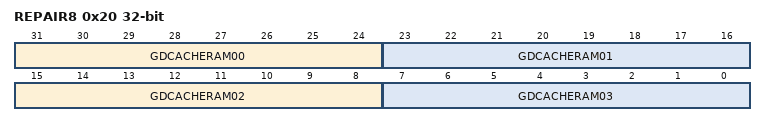
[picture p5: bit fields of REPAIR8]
  0x20 REPAIR8 — SRAM repair register 8
    [31-8n:24-8n] GDCACHERAM{n:02} (n=0..3) — GD Cache Data Ram {n}
